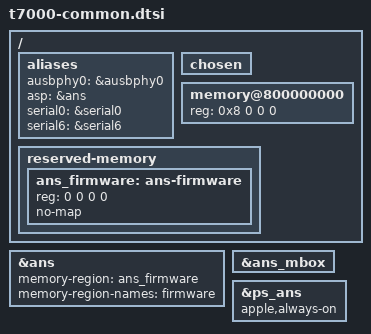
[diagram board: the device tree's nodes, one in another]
// SPDX-License-Identifier: GPL-2.0+ OR MIT
/*
 * Apple TV HD, iPhone 6, iPhone 6 Plus, iPad mini 4, iPod touch 6
 *
 * This file contains parts common to all Apple A8 devices.
 *
 * target-type: J42d, J96, J97, N56, N61, N102
 *
 * Copyright (c) 2024, Nick Chan <towinchenmi@gmail.com>
 */

/ {
	aliases {
		ausbphy0 = &ausbphy0; /* Used by loader */
		asp = &ans;
		serial0 = &serial0;
		serial6 = &serial6;
	};

	chosen {
		#address-cells = <2>;
		#size-cells = <2>;
		ranges;
	};

	memory@800000000 {
		device_type = "memory";
		reg = <0x8 0 0 0>; /* To be filled by loader */
	};

	reserved-memory {
		#address-cells = <2>;
		#size-cells = <2>;
		ranges;

		ans_firmware: ans-firmware {
			/* Filled in by bootloder */
			reg = <0 0 0 0>;
			no-map;
		};
		/* To be filled by loader */
	};
};

/*
 * Internal NAND through the ANS1 storage processor, on every A8 board (the
 * ADT ans node is the same on N102, N56 and N61, and J96/J97 have the J81's
 * iOS 15 form of it). The boot loader started its firmware and iOS never
 * shuts it down (no-shutdown in the ADT), so keep its power domain on.
 */
&ans {
	memory-region = <&ans_firmware>;
	memory-region-names = "firmware";
	status = "okay";
};

&ans_mbox {
	status = "okay";
};

&ps_ans {
	apple,always-on;
};
